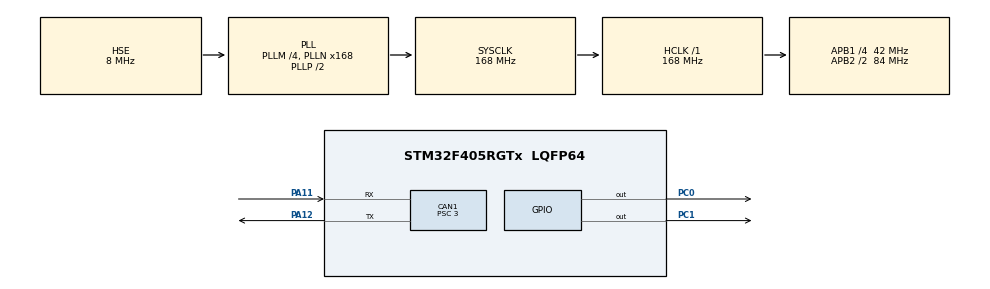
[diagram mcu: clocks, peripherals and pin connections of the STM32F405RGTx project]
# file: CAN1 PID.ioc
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CAN1.BS1=CAN_BS1_6TQ
CAN1.BS2=CAN_BS2_8TQ
CAN1.CalculateBaudRate=933333
CAN1.CalculateTimeBit=1071.42
CAN1.CalculateTimeQuantum=71.42857142857143
CAN1.NART=ENABLE
CAN1.Prescaler=3
Mcu.Family=STM32F4
Mcu.Name=STM32F405RGTx
Mcu.Package=LQFP64
NVIC.CAN1_RX0_IRQn=true\:0\:0\:false\:false\:true\:true\:true
NVIC.PriorityGroup=NVIC_PRIORITYGROUP_4
NVIC.TIM2_IRQn=true\:0\:0\:false\:false\:true\:true\:true
PA11.Mode=CAN_Activate
PA11.Signal=CAN1_RX
PA12.Mode=CAN_Activate
PA12.Signal=CAN1_TX
PC0.GPIO_Speed=GPIO_SPEED_FREQ_HIGH
PC0.PinState=GPIO_PIN_SET
PC0.Signal=GPIO_Output
PC1.GPIO_Speed=GPIO_SPEED_FREQ_HIGH
PC1.PinState=GPIO_PIN_SET
PC1.Signal=GPIO_Output
PH0-OSC_IN.Mode=HSE-External-Oscillator
PH0-OSC_IN.Signal=RCC_OSC_IN
PH1-OSC_OUT.Mode=HSE-External-Oscillator
PH1-OSC_OUT.Signal=RCC_OSC_OUT
ProjectManager.HeapSize=0x200
ProjectManager.StackSize=0x400
ProjectManager.TargetToolchain=MDK-ARM V5.27
RCC.48MHZClocksFreq_Value=84000000
RCC.AHBFreq_Value=168000000
RCC.APB1CLKDivider=RCC_HCLK_DIV4
RCC.APB1Freq_Value=42000000
RCC.APB1TimFreq_Value=84000000
RCC.APB2CLKDivider=RCC_HCLK_DIV2
RCC.APB2Freq_Value=84000000
RCC.APB2TimFreq_Value=168000000
RCC.CortexFreq_Value=168000000
RCC.HCLKFreq_Value=168000000
RCC.HSE_VALUE=8000000
RCC.HSI_VALUE=16000000
RCC.LSE_VALUE=32768
RCC.PLLM=4
RCC.PLLN=168
RCC.PLLSourceVirtual=RCC_PLLSOURCE_HSE
RCC.SYSCLKFreq_VALUE=168000000
RCC.SYSCLKSource=RCC_SYSCLKSOURCE_PLLCLK
RCC.VCOOutputFreq_Value=336000000
TIM2.AutoReloadPreload=TIM_AUTORELOAD_PRELOAD_ENABLE
TIM2.Period=1000-1
TIM2.Prescaler=7200-1
VP_TIM2_VS_ClockSourceINT.Mode=Internal
board=custom

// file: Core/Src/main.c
/* USER CODE BEGIN Header */
/**
  ******************************************************************************
  * @file           : main.c
  * @brief          : Main program body
  ******************************************************************************
  * @attention
  *
  * <h2><center>&copy; Copyright (c) 2021 STMicroelectronics.
  * All rights reserved.</center></h2>
  *
  * This software component is licensed by ST under BSD 3-Clause license,
  * the "License"; You may not use this file except in compliance with the
  * License. You may obtain a copy of the License at:
  *                        opensource.org/licenses/BSD-3-Clause
  *
  ******************************************************************************
  */
/* USER CODE END Header */
#include "main.h"
#include "can.h"
#include "tim.h"
#include "gpio.h"

/* USER CODE BEGIN Includes */
#include "robo_base.h"
/* USER CODE END Includes */

/* USER CODE BEGIN PTD */
Speed_System Speed_Sys;		//速度环控电机
/* USER CODE END PTD */

void SystemClock_Config(void);

int main(void)
{

  /* MCU Configuration--------------------------------------------------------*/

  /* Reset of all peripherals, Initializes the Flash interface and the Systick. */
  HAL_Init();

  /* Configure the system clock */
  SystemClock_Config();

  /* Initialize all configured peripherals */
  MX_GPIO_Init();
  MX_CAN1_Init();
  MX_TIM2_Init();
  /* USER CODE BEGIN 2 */
	HAL_TIM_Base_Start_IT(&htim2);
	CAN_FilterInit();//过滤器初始化
	PID_Init(&Speed_Sys.Speed_PID,1,0,0,4000,100,0,3000);//最大误差4000 容许死线100 转速3000 //最大误差如果设太小，小于3000，电机开始时会由于速度为零，误差为3000，最大误差为1000，导致无限反转，无法转起来
	HAL_GPIO_WritePin(GPIOC,GPIO_PIN_1,GPIO_PIN_RESET);
  /* USER CODE END 2 */

  /* Infinite loop */
  while (1)
  {

  }
}

void SystemClock_Config(void)
{
  RCC_OscInitTypeDef RCC_OscInitStruct = {0};
  RCC_ClkInitTypeDef RCC_ClkInitStruct = {0};

  /** Configure the main internal regulator output voltage
  */
  __HAL_RCC_PWR_CLK_ENABLE();
  __HAL_PWR_VOLTAGESCALING_CONFIG(PWR_REGULATOR_VOLTAGE_SCALE1);
  /** Initializes the RCC Oscillators according to the specified parameters
  * in the RCC_OscInitTypeDef structure.
  */
  RCC_OscInitStruct.OscillatorType = RCC_OSCILLATORTYPE_HSE;
  RCC_OscInitStruct.HSEState = RCC_HSE_ON;
  RCC_OscInitStruct.PLL.PLLState = RCC_PLL_ON;
  RCC_OscInitStruct.PLL.PLLSource = RCC_PLLSOURCE_HSE;
  RCC_OscInitStruct.PLL.PLLM = 4;
  RCC_OscInitStruct.PLL.PLLN = 168;
  RCC_OscInitStruct.PLL.PLLP = RCC_PLLP_DIV2;
  RCC_OscInitStruct.PLL.PLLQ = 4;
  if (HAL_RCC_OscConfig(&RCC_OscInitStruct) != HAL_OK)
  {
    Error_Handler();
  }
  /** Initializes the CPU, AHB and APB buses clocks
  */
  RCC_ClkInitStruct.ClockType = RCC_CLOCKTYPE_HCLK|RCC_CLOCKTYPE_SYSCLK
                              |RCC_CLOCKTYPE_PCLK1|RCC_CLOCKTYPE_PCLK2;
  RCC_ClkInitStruct.SYSCLKSource = RCC_SYSCLKSOURCE_PLLCLK;
  RCC_ClkInitStruct.AHBCLKDivider = RCC_SYSCLK_DIV1;
  RCC_ClkInitStruct.APB1CLKDivider = RCC_HCLK_DIV4;
  RCC_ClkInitStruct.APB2CLKDivider = RCC_HCLK_DIV2;

  if (HAL_RCC_ClockConfig(&RCC_ClkInitStruct, FLASH_LATENCY_5) != HAL_OK)
  {
    Error_Handler();
  }
}

void Error_Handler(void)
{
  __disable_irq();
  while (1)
  {
  }
}

/************************ (C) COPYRIGHT STMicroelectronics *****END OF FILE****/
